# KM1M7CF13 register map
Vendor: Nuvoton Technology Corporation Japan; Series: KM1M7CF; File version: 1.0.3
CPU: CM7 r1p2, little endian, MPU, FPU, double-precision FPU, I-cache, D-cache, ITCM, DTCM, 4 interrupt priority bits
Registers are 32-bit, read-write, no defined reset value unless marked. A register's access mark holds for its fields unless they carry their own. Offsets are from the block's base; [hi:lo] are bit positions; {n}, {i} and the like mark numbered series.

## CRYPTO
Base 0x40300000
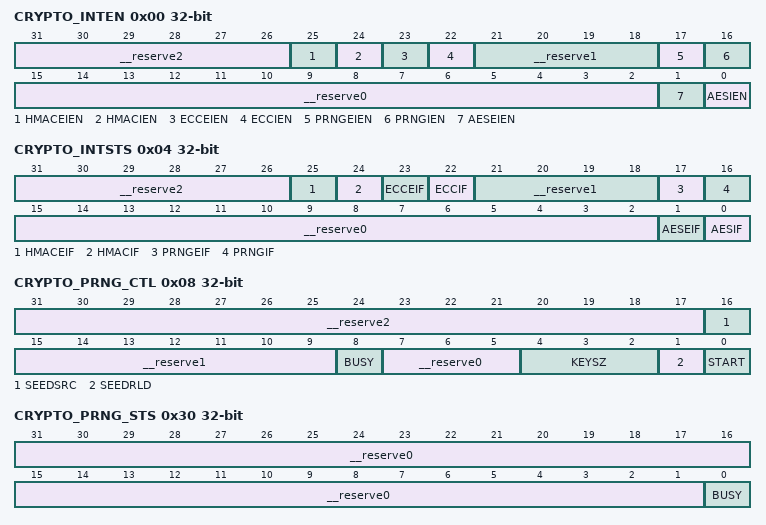
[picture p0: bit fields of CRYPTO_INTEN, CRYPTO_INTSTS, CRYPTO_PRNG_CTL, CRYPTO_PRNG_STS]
0x00 CRYPTO_INTEN access per field — Crypto Interrupt Enable Control Register
  [31:26] __reserve2 ro — "0" is always read out.
  [25] HMACEIEN rw — SHA/HMAC Error Interrupt Enable Bit
  [24] HMACIEN rw — SHA/HMAC Interrupt Enable Bit
  [23] ECCEIEN rw — ECC Error Interrupt Enable Bit
  [22] ECCIEN rw — ECC Interrupt Enable Bit
  [21:18] __reserve1 rw — "0" is always read out.
  [17] PRNGEIEN rw — PRNG Error Flag Enable Bit
  [16] PRNGIEN rw — PRNG Interrupt Enable Bit
  [15:2] __reserve0 rw — "0" is always read out.
  [1] AESEIEN rw — AES Error Flag Enable Bit
  [0] AESIEN rw — AES Interrupt Enable Bit
0x04 CRYPTO_INTSTS — Crypto Interrupt Flag
  [31:26] __reserve2 — "0" is always read out.
  [25] HMACEIF — SHA/HMAC Error Flag
  [24] HMACIF — SHA/HMAC Finish Interrupt Flag
  [23] ECCEIF — ECC Error Flag
  [22] ECCIF — ECC Finish Interrupt Flag
  [21:18] __reserve1 — "0" is always read out.
  [17] PRNGEIF — PRNG Error Flag
  [16] PRNGIF — PRNG Finish Interrupt Flag
  [15:2] __reserve0 — "0" is always read out.
  [1] AESEIF — AES Error Flag
  [0] AESIF — AES Finish Interrupt Flag
0x08 CRYPTO_PRNG_CTL access per field — PRNG Control Register
  [31:17] __reserve2 rw — "0" is always read out.
  [16] SEEDSRC rw — Seed Source
  [15:9] __reserve1 rw — "0" is always read out.
  [8] BUSY ro — PRNG Busy (Read Only)
  [7:5] __reserve0 rw — "0" is always read out.
  [4:2] KEYSZ rw — PRNG Generate Key Size
  [1] SEEDRLD rw — Reload New Seed for PRNG Engine
  [0] START rw — Start PRNG Engine
0x0C CRYPTO_PRNG_SEED wo — Seed for PRNG
  [31:0] SEED — Seed for PRNG (Write Only)
{0x10+4i} CRYPTO_PRNG_KEY{i} ro (i=0..7) — PRNG Ge{i}erated Key0
  [31:0] KEY — Store PRNG Generated Key (Read Only)
0x30 CRYPTO_PRNG_STS ro — PRNG Status Register
  [31:1] __reserve0 — "0" is always read out.
  [0] BUSY — PRNG Busy Flag
{0x50+4i} CRYPTO_AES_FDBCK{i} ro (i=0..3) — AES E{i}gine Output Feedback Data After Cryptographic Operation
  [31:0] FDBCK — AES Feedback Information
0x80 CRYPTO_AES_GCM_IVCNT0 — AES GCM IV Byte Count Register 0
  [31:0] CNT — AES GCM IV Byte Count
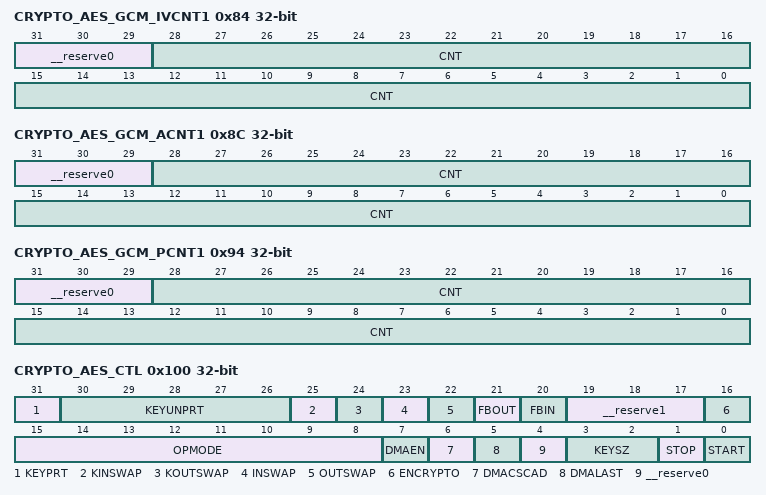
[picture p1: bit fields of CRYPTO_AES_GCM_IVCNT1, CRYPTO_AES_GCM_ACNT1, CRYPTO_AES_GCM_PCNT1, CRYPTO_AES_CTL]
0x84 CRYPTO_AES_GCM_IVCNT1 — AES GCM IV Byte Count Register 1
  [31:29] __reserve0 — "0" is always read out.
  [28:0] CNT — AES GCM IV Byte Count
0x88 CRYPTO_AES_GCM_ACNT0 — AES GCM A Byte Count Register 0
  [31:0] CNT — AES GCM a Byte Count
0x8C CRYPTO_AES_GCM_ACNT1 — AES GCM A Byte Count Register 1
  [31:29] __reserve0 — "0" is always read out.
  [28:0] CNT — AES GCM a Byte Count
0x90 CRYPTO_AES_GCM_PCNT0 — AES GCM P Byte Count Register 0
  [31:0] CNT — AES GCM P Byte Count
0x94 CRYPTO_AES_GCM_PCNT1 — AES GCM P Byte Count Register 1
  [31:29] __reserve0 — "0" is always read out.
  [28:0] CNT — AES GCM P Byte Count
0xA0 CRYPTO_AES_FBADDR — AES DMA Feedback Address Register
  [31:0] FBADDR — AES DMA Feedback Address
0x100 CRYPTO_AES_CTL — AES Control Register
  [31] KEYPRT — Protect Key
  [30:26] KEYUNPRT — Unprotect Key
  [25] KINSWAP — AES Engine Input Key and Initial Vector Swap
  [24] KOUTSWAP — AES Engine Output Key, Initial Vector and Feedback Swap
  [23] INSWAP — AES Engine Input Data Swap
  [22] OUTSWAP — AES Engine Output Data Swap
  [21] FBOUT — Feedback Output From AES Via DMA Automatically
  [20] FBIN — Feedback Input to AES Via DMA Automatically
  [19:17] __reserve1 — "0" is always read out.
  [16] ENCRYPTO — AES Encryption/Decryption
  [15:8] OPMODE — AES Engine Operation Modes
  [7] DMAEN — AES Engine DMA Enable Bit
  [6] DMACSCAD — AES Engine DMA with Cascade Mode
  [5] DMALAST — AES Last Block
  [4] __reserve0 — "0" is always read out.
  [3:2] KEYSZ — AES Key Size
  [1] STOP — AES Engine Stop
  [0] START — AES Engine Start
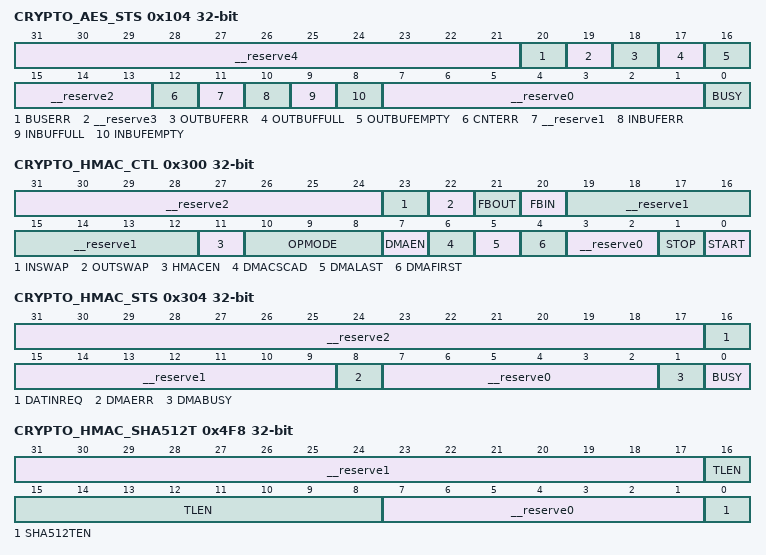
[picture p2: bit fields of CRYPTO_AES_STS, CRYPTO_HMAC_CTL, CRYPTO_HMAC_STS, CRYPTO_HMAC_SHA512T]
0x104 CRYPTO_AES_STS ro — AES Engine Flag
  [31:21] __reserve4 — "0" is always read out.
  [20] BUSERR — AES DMA Access Bus Error Flag
  [19] __reserve3 — "0" is always read out.
  [18] OUTBUFERR — AES Out Buffer Error Flag
  [17] OUTBUFFULL — AES Out Buffer Full Flag
  [16] OUTBUFEMPTY — AES Out Buffer Empty
  [15:13] __reserve2 — "0" is always read out.
  [12] CNTERR — CRYPTO_AES_CNT Setting Error
  [11] __reserve1 — "0" is always read out.
  [10] INBUFERR — AES Input Buffer Error Flag
  [9] INBUFFULL — AES Input Buffer Full Flag
  [8] INBUFEMPTY — AES Input Buffer Empty
  [7:1] __reserve0 — "0" is always read out.
  [0] BUSY — AES Engine Busy
0x108 CRYPTO_AES_DATIN — AES Engine Data Input Port Register
  [31:0] DATIN — AES Engine Input Port
0x10C CRYPTO_AES_DATOUT ro — AES Engine Data Output Port Register
  [31:0] DATOUT — AES Engine Output Port
{0x110+4i} CRYPTO_AES_KEY{i} (i=0..7) — AES Key Word 0 Register
  [31:0] KEY — CRYPTO_AES_KEYx
{0x130+4i} CRYPTO_AES_IV{i} (i=0..3) — AES I{i}itial Vector Word 0 Register
  [31:0] IV — AES Initial Vectors
0x140 CRYPTO_AES_SADDR — AES DMA Source Address Register
  [31:0] SADDR — AES DMA Source Address
0x144 CRYPTO_AES_DADDR — AES DMA Destination Address Register
  [31:0] DADDR — AES DMA Destination Address
0x148 CRYPTO_AES_CNT — AES Byte Count Register
  [31:0] CNT — AES Byte Count
0x300 CRYPTO_HMAC_CTL — SHA/HMAC Control Register
  [31:24] __reserve2 — "0" is always read out.
  [23] INSWAP — SHA/HMAC Engine Input Data Swap
  [22] OUTSWAP — SHA/HMAC Engine Output Data Swap
  [21] FBOUT — Feedback Output From SHA/HMAC Via DMA Automatically
  [20] FBIN — Feedback Input to SHA/HMAC Via DMA Automatically
  [19:12] __reserve1 — "0" is always read out.
  [11] HMACEN — HMAC_SHA Engine Operating Mode
  [10:8] OPMODE — SHA/HMAC Engine Operation Modes
  [7] DMAEN — SHA/HMAC Engine DMA Enable Bit
  [6] DMACSCAD — SHA/HMAC Engine DMA with Cascade Mode
  [5] DMALAST — SHA/HMAC Last Block
  [4] DMAFIRST — SHA/HMAC First Block in Cascade function
  [3:2] __reserve0 — "0" is always read out.
  [1] STOP — SHA/HMAC Engine Stop
  [0] START — SHA/HMAC Engine Start
0x304 CRYPTO_HMAC_STS ro — SHA/HMAC Status Flag
  [31:17] __reserve2 — "0" is always read out.
  [16] DATINREQ — SHA/HMAC Non-DMA Mode Data Input Request
  [15:9] __reserve1 — "0" is always read out.
  [8] DMAERR — SHA/HMAC Engine DMA Error Flag
  [7:2] __reserve0 — "0" is always read out.
  [1] DMABUSY — SHA/HMAC Engine DMA Busy Flag
  [0] BUSY — SHA/HMAC Engine Busy
{0x308+4i} CRYPTO_HMAC_DGST{i} ro (i=0..15) — SHA/HMAC Output Feedback Data 0
  [31:0] DGST — SHA/HMAC Output Feedback Data Output Register
0x348 CRYPTO_HMAC_KEYCNT — SHA/HMAC Key Byte Count Register
  [31:0] KEYCNT — SHA/HMAC Key Byte Count
0x34C CRYPTO_HMAC_SADDR — SHA/HMAC DMA Source Address Register
  [31:0] SADDR — SHA/HMAC DMA Source Address
0x350 CRYPTO_HMAC_DMACNT — SHA/HMAC Byte Count Register
  [31:0] DMACNT — SHA/HMAC Operation Byte Count
0x354 CRYPTO_HMAC_DATIN — SHA/HMAC Engine Non-dMA Mode Data Input Port Register
  [31:0] DATIN — SHA/HMAC Engine Input Port
{0x358+4i} CRYPTO_HMAC_FDBCK{i} (i=0..53) — SHA/HMAC Output Feedback Data 0 After SHA/HMAC Operatio{i}
  [31:0] FDBCK — SHA/HMAC Feedback Information
0x4F8 CRYPTO_HMAC_SHA512T — SHA/HMAC SHA512/t Control Register
  [31:17] __reserve1 — "0" is always read out.
  [16:8] TLEN — SHA512/t output digest length
  [7:1] __reserve0 — "0" is always read out.
  [0] SHA512TEN — SHA512/t Engine Enable Bit
0x4FC CRYPTO_HMAC_FBADDR — SHA/HMAC DMA Feedback Address Register
  [31:0] FBADDR — SHA/HMAC DMA Feedback Address
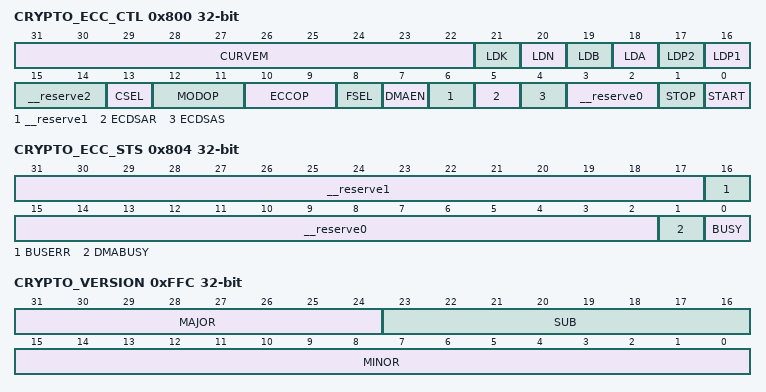
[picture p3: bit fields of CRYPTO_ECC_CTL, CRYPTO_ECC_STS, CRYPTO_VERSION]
0x800 CRYPTO_ECC_CTL — ECC Control Register
  [31:22] CURVEM — The key length of elliptic curve.
  [21] LDK — The Control Signal of Register for SCALARK
  [20] LDN — The Control Signal of Register for the Parameter CURVEN of Elliptic Curve
  [19] LDB — The Control Signal of Register for the Parameter CURVEB of Elliptic Curve
  [18] LDA — The Control Signal of Register for the Parameter CURVEA of Elliptic Curve
  [17] LDP2 — The Control Signal of Register POINTX2 and POINTY2 for the x and Y Coordinate of the Second Point
  [16] LDP1 — The Control Signal of Register POINTX1 and POINTY1 for the x and Y Coordinate of the First Point
  [15:14] __reserve2 — "0" is always read out.
  [13] CSEL — Curve Selection
  [12:11] MODOP — Modulus Operation for PF
  [10:9] ECCOP — Point Operation for BF and PF
  [8] FSEL — Field Selection
  [7] DMAEN — ECC Accelerator DMA Enable Bit
  [6] __reserve1 — "0" is always read out.
  [5] ECDSAR — Generate R in ECDSA Signature Generation
  [4] ECDSAS — Generate S in ECDSA Signature Generation
  [3:2] __reserve0 — "0" is always read out.
  [1] STOP — ECC Accelerator Stop
  [0] START — ECC Accelerator Start
0x804 CRYPTO_ECC_STS ro — ECC Status Register
  [31:17] __reserve1 — "0" is always read out.
  [16] BUSERR — ECC DMA Access Bus Error Flag
  [15:2] __reserve0 — "0" is always read out.
  [1] DMABUSY — ECC DMA Busy Flag
  [0] BUSY — ECC Accelerator Busy Flag
{0x808+4i} CRYPTO_ECC_X1_{i} (i=0..17) — ECC the X-coordi{i}ate Word0 of the First Point
  [31:0] POINTX1 — ECC the X-coordinate Value of the First Point
{0x850+4i} CRYPTO_ECC_Y1_{i} (i=0..17) — ECC the Y-coordi{i}ate Word0 of the First Point
  [31:0] POINTY1 — ECC the Y-coordinate Value of the First Point
{0x898+4i} CRYPTO_ECC_X2_{i} (i=0..17) — ECC the X-coordi{i}ate Word0 of the Second Point
  [31:0] POINTX2 — ECC the X-coordinate Value of the Second Point
{0x8E0+4i} CRYPTO_ECC_Y2_{i} (i=0..17) — ECC the Y-coordi{i}ate Word0 of the Second Point
  [31:0] POINTY2 — ECC the Y-coordinate Value of the Second Point
{0x928+4i} CRYPTO_ECC_A_{i} (i=0..17) — ECC the Parameter CURVEA Word0 of Elliptic Curve
  [31:0] CURVEA — ECC the Parameter CURVEA Value of Elliptic Curve
{0x970+4i} CRYPTO_ECC_B_{i} (i=0..17) — ECC the Parameter CURVEB Word0 of Elliptic Curve
  [31:0] CURVEB — ECC the Parameter CURVEB Value of Elliptic Curve
{0x9B8+4i} CRYPTO_ECC_N_{i} (i=0..17) — ECC the Parameter CURVEN Word0 of Elliptic Curve
  [31:0] CURVEN — ECC the Parameter CURVEN Value of Elliptic Curve
{0xA00+4i} CRYPTO_ECC_K_{i} wo (i=0..17) — ECC the Scalar SCALARK Word0 of Poi{i}t Multiplication
  [31:0] SCALARK — ECC the Scalar SCALARK Value of Point Multiplication
0xA48 CRYPTO_ECC_SADDR — ECC DMA Source Address Register
  [31:0] SADDR — ECC DMA Source Address
0xA4C CRYPTO_ECC_DADDR — ECC DMA Destination Address Register
  [31:0] DADDR — ECC DMA Destination Address
0xA50 CRYPTO_ECC_STARTREG — ECC Starting Address of Updated Registers
0xA54 CRYPTO_ECC_WORDCNT — ECC DMA Word Count
0xFFC CRYPTO_VERSION ro — Crypto Design Version Register
  [31:24] MAJOR — RTL Design Major Version Number
  [23:16] SUB — RTL Design Sub Version Number
  [15:0] MINOR — RTL Design Minor Version Number
